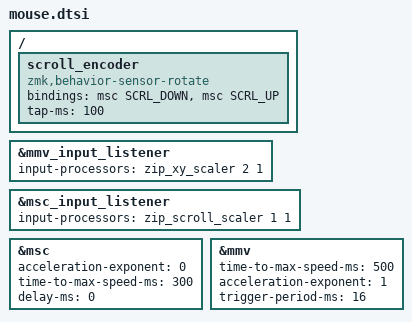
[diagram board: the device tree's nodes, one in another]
#define ZMK_POINTING_DEFAULT_MOVE_VAL 600 // 600
#define ZMK_POINTING_DEFAULT_SCRL_VAL 20  // 10

#include <dt-bindings/zmk/pointing.h>
#include <input/processors.dtsi>
#include <zephyr/dt-bindings/input/input-event-codes.h>

&mmv_input_listener { input-processors = <&zip_xy_scaler 2 1>; };
&msc_input_listener { input-processors = <&zip_scroll_scaler 1 1>; };

&msc {
    acceleration-exponent = <0>;      // 0
    time-to-max-speed-ms = <300>;     // 300
    delay-ms = <0>;                   // 0
};

&mmv {
    time-to-max-speed-ms = <500>;
    acceleration-exponent = <1>;
    trigger-period-ms = <16>;
};

/ {
    scroll_encoder: scroll_encoder {
        compatible = "zmk,behavior-sensor-rotate";
        #sensor-binding-cells = <0>;
        bindings = <&msc SCRL_DOWN>, <&msc SCRL_UP>;
        tap-ms = <100>;
    };
};
